# MINI51AN_v1 register map
File version: 1.0
Registers are 32-bit, read-write, reset 0x0 unless marked. A register's access mark holds for its fields unless they carry their own. Offsets are from the block's base; [hi:lo] are bit positions; {n}, {i} and the like mark numbered series; 'fields as' and 'values as' point back to an identical list.

## ADC — ADC Register Map
Base 0x400E0000
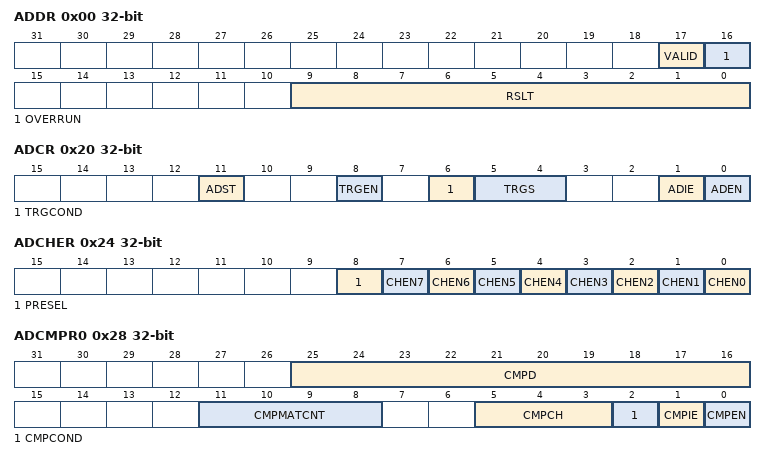
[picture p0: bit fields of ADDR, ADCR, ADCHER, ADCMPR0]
0x00 ADDR ro — A/D Data Register
  [17] VALID — Valid Flag. This bit is set to 1 when ADC conversion is completed and cleared by hardware after the ADDR register is read.
    0=Data in RSLT[9:0] bits not valid; 1=Data in RSLT[9:0] bits valid
  [16] OVERRUN — Over Run Flag. If converted data in RSLT[9:0] has not been read before the new conversion result is loaded to this register, OVERRUN is set to 1. It is cleared by hardware after the ADDR register is read.
    0=Data in RSLT[9:0] is recent conversion result; 1=Data in RSLT[9:0] overwritten
  [9:0] RSLT — A/D Conversion Result. This field contains conversion result of ADC.
0x20 ADCR — A/D Control Register
  [11] ADST — A/D Conversion Start. ADST bit can be set to 1 from two sources: software and external pin STADC. ADST will be cleared to 0 by hardware automatically.
    0=Conversion stopped and A/D converter entered idle state; 1=Conversion start
  [8] TRGEN — External Trigger Enable. Enable or disable triggering of A/D conversion by external STADC pin.
    0=Disabled; 1=Enabled
  [6] TRGCOND — External Trigger Condition. This bit decides whether the external pin STADC trigger event is falling or raising edge. The signal must be kept at stable state at least 4 PCLKs at high and low state for edge trigger.
    0=Falling edge; 1=Raising edge
  [5:4] TRGS — Hardware Trigger Source. Software should disable TRGEN and ADST before change TRGS. In hardware trigger mode, the ADST bit is set by the external trigger from STADC.
    0=A/D conversion is started by external STADC pin; 3=A/D conversion is started by PWM trigger
  [1] ADIE — A/D Interrupt Enable. A/D conversion end interrupt request is generated if ADIE bit is set to 1.
    0=A/D interrupt function Disabled; 1=A/D interrupt function Enabled
  [0] ADEN — A/D Converter Enable. Before starting the A/D conversion function, this bit should be set to 1. Clear it to 0 to disable A/D converter analog circuit power consumption.
    0=Disabled; 1=Enabled
0x24 ADCHER — A/D Channel Enable Register
  [8] PRESEL — Analog Input Channel 7 Selection. Note: When software selects the band-gap voltage as the analog input source of ADC channel 7, the ADC clock rate needs to be limited to lower than 300 kHz.
    0=Analog Input Channel 7; 1=Band-gap (VBG) Analog Input
  [n] CHEN{n} (n=1..7) — Analog Input Channel {n} Enable
    0=Disabled; 1=Enabled
  [0] CHEN0 — Analog Input Channel 0 Enable. Note: If software enables more than one channel, the channel with the lowest number will be selected and the other enabled channels will be ignored. That means channel 0 is the highest priority.
    0=Disabled; 1=Enabled
0x28 ADCMPR0 — A/D Compare Register 0
  [25:16] CMPD — Comparison Data. The 10-bit data is used to compare with conversion result of specified channel.
  [11:8] CMPMATCNT — Compare Match Count. When the specified A/D channel analog conversion result matches the compare condition defined by CMPCOND[2], the internal match counter will increase 1. When the internal counter reaches the value to (CMPMATCNT +1), the CMPFx bit will be set.
  [5:3] CMPCH — Compare Channel Selection
  [2] CMPCOND — Compare Condition. Note: When the internal counter reaches the value to (CMPMATCNT +1), the CMPFx bit will be set.
    0=Set the compare condition as that when a 10-bit A/D conversion result is less than the 10-bit CMPD (ADCMPRx[27:16]), the internal match counter will increase one; 1=Set the compare condition as that when a 10-bit A/D conversion result is greater or equal to the 10-bit CMPD (ADCMPRx[27:16]), the internal match counter will increase one
  [1] CMPIE — Compare Interrupt Enable. If the compare function is enabled and the compare condition matches the setting of CMPCOND and CMPMATCNT, CMPFx bit will be asserted, in the meanwhile, if CMPIE is set to 1, a compare interrupt request is generated.
    0=Compare function interrupt Disabled; 1=Compare function interrupt Enabled
  [0] CMPEN — Compare Enable. Set 1 to this bit to enable comparing CMPD[9:0] with specified channel conversion results when converted data is loaded into the ADDR register.
    0=Compare function Disabled; 1=Compare function Enabled
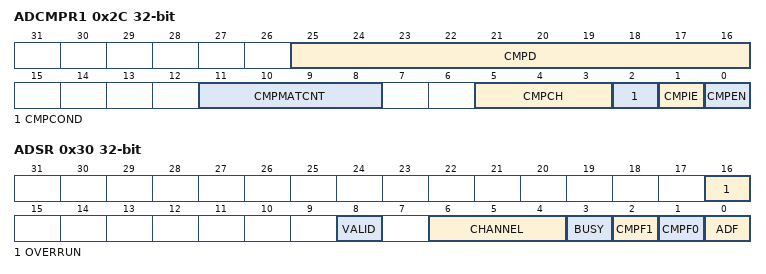
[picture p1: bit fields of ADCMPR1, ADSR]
0x2C ADCMPR1 — A/D Compare Register 1
  fields as ADCMPR0
0x30 ADSR — A/D Status Register
  [16] OVERRUN — Over Run Flag. It is a mirror to OVERRUN bit in ADDR.
  [8] VALID — Data Valid Flag. It is a mirror of VALID bit in ADDR.
  [6:4] CHANNEL — Current Conversion Channel. It is read only.
  [3] BUSY — BUSY/IDLE. This bit is mirror of as ADST bit in ADCR. It is read only.
    0=A/D converter is in idle state; 1=A/D converter is busy at conversion
  [2] CMPF1 — Compare Flag #1. When the selected channel A/D conversion result meets the setting condition in ADCMPR1, this bit is set to 1. Software can write 1 to clear this bit to zero.
    0=Conversion result in ADDR does not meet the ADCMPR1 setting; 1=Conversion result in ADDR meets the ADCMPR1 setting
  [1] CMPF0 — Compare Flag #0. When the selected channel A/D conversion result meets the setting condition in ADCMPR0, this bit is set to 1. Software can write 1 to clear this bit to zero.
    0=Conversion result in ADDR does not meet the ADCMPR0 setting; 1=Conversion result in ADDR meets the ADCMPR0 setting
  [0] ADF — A/D Conversion End Flag. A status flag that indicates the end of A/D conversion. ADF is set to 1 When A/D conversion ends. Software can write 1 to clear this bit to zero.
0x44 ADTDCR — A/D Trigger Delay Control Register
  [7:0] PTDT — PWM Trigger Delay Timer. Set this field will delay ADC start conversion time after PWM trigger is coming. PWM trigger delay time is (4 * PTDT) * system clock
